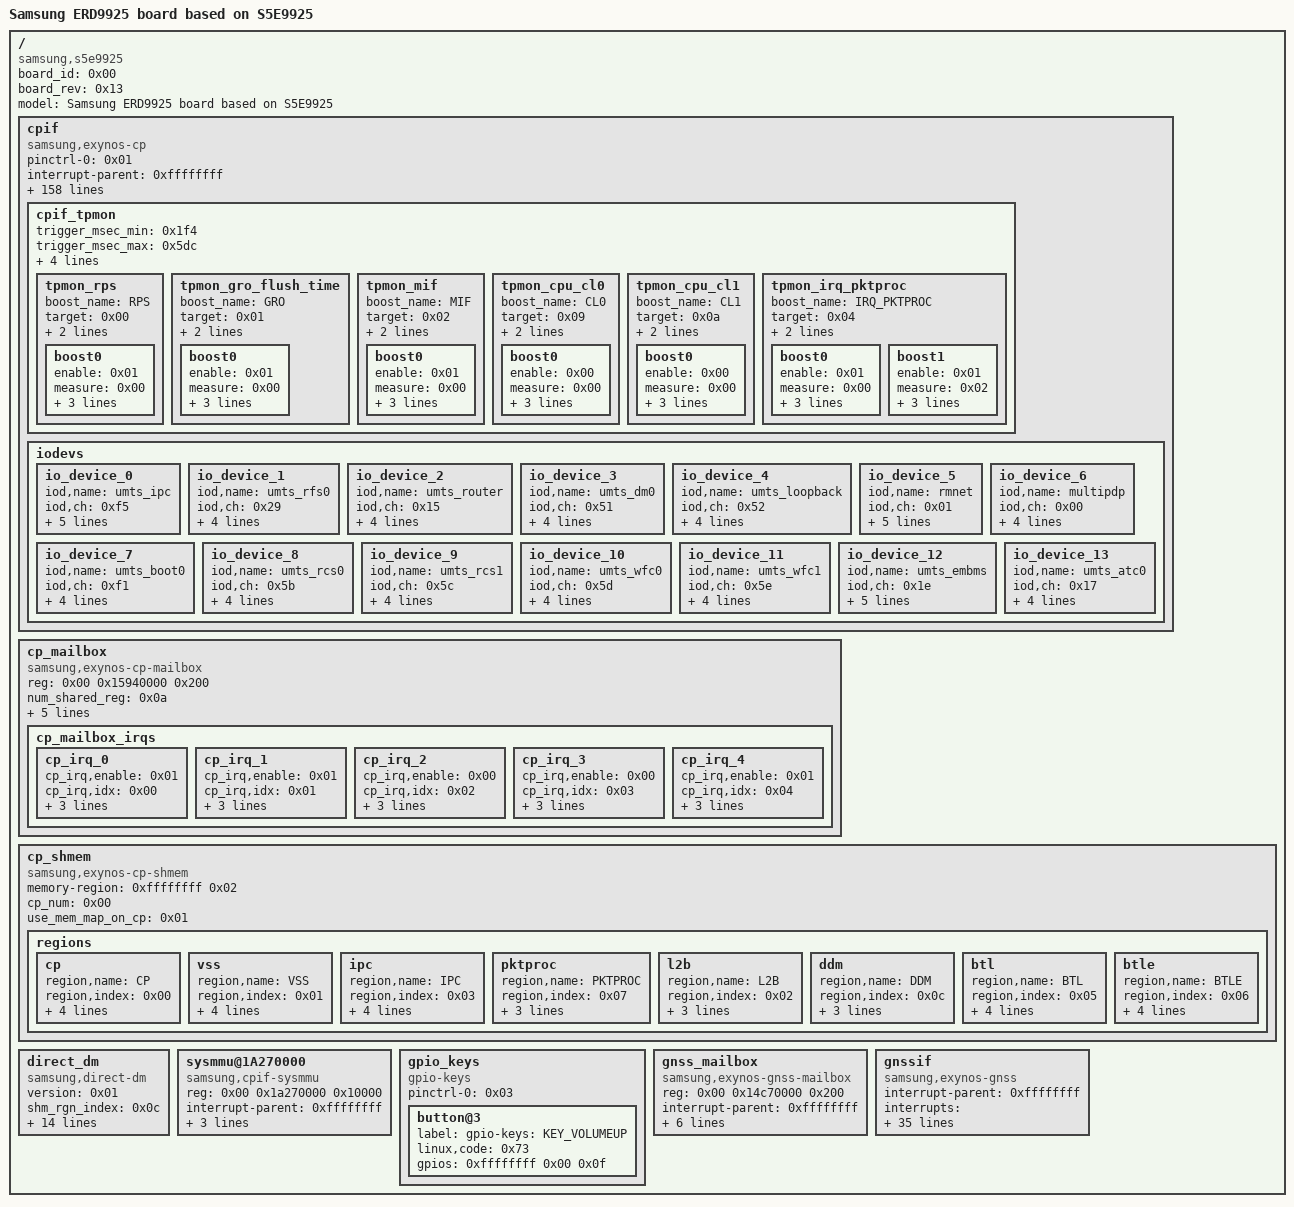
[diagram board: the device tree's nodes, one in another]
/dts-v1/;

/ {
	compatible = "samsung,s5e9925\0samsung,ERD9925";
	board_id = <0x00>;
	board_rev = <0x13>;

	fragment@modemif {
		target-path = "/";

		__overlay__ {
			#address-cells = <0x02>;
			#size-cells = <0x01>;

			cpif {
				compatible = "samsung,exynos-cp";
				status = "okay";
				pinctrl-names = "default";
				pinctrl-0 = <0x01>;
				interrupt-parent = <0xffffffff>;
				interrupts = <0x00 0x275 0x04>;
				interrupt-names = "RESET_REQ";
				ap2cp_cfg_addr = <0x19020000>;
				mif,name = "s5133ap";
				mif,cp_num = <0x00>;
				mif,modem_type = <0x00>;
				mif,protocol = <0x01>;
				mif,ipc_version = <0x32>;
				mif,link_type = <0x00>;
				mif,link_name = "shmem";
				mif,link_attrs = <0x7c8>;
				mif,interrupt_types = <0x00>;
				mif,capability_check = <0x01>;
				mif,int_ap2cp_msg = <0x00>;
				mif,int_ap2cp_wakeup = <0x01>;
				mif,int_ap2cp_status = <0x02>;
				mif,int_ap2cp_active = <0x03>;
				mif,int_ap2cp_lcd_status = <0x04>;
				mif,int_ap2cp_llc_status = <0x05>;
				mif,int_ap2cp_clatinfo_send = <0x06>;
				mif,int_ap2cp_uart_noti = <0x0f>;
				mif,irq_cp2ap_msg = <0x00>;
				mif,irq_cp2ap_status = <0x02>;
				mif,irq_cp2ap_active = <0x03>;
				mif,irq_cp2ap_llc_status = <0x05>;
				mif,irq_cp2ap_clatinfo_ack = <0x06>;
				mif,irq_cp2ap_wakelock = <0x08>;
				mif,irq_cp2ap_ratmode = <0x09>;
				legacy_fmt_head_tail_offset = <0x10>;
				legacy_fmt_buffer_offset = <0x1000>;
				legacy_fmt_txq_size = <0x1000>;
				legacy_fmt_rxq_size = <0x1000>;
				legacy_raw_head_tail_offset = <0x20>;
				legacy_raw_buffer_offset = <0x3000>;
				legacy_raw_txq_size = <0x1fd000>;
				legacy_raw_rxq_size = <0x200000>;
				legacy_raw_qos_head_tail_offset = <0x30>;
				legacy_raw_qos_buffer_offset = <0x400000>;
				legacy_raw_qos_txq_size = <0x100000>;
				legacy_raw_qos_rxq_size = <0x100000>;
				legacy_raw_rx_buffer_cached = <0x00>;
				offset_cmsg_offset = <0x60>;
				offset_srinfo_offset = <0x64>;
				offset_clk_table_offset = <0x68>;
				offset_buff_desc_offset = <0x6c>;
				offset_capability_offset = <0x70>;
				cmsg_offset = <0xc0>;
				srinfo_offset = <0x300>;
				srinfo_size = <0x800>;
				clk_table_offset = <0x200>;
				buff_desc_offset = <0xc00>;
				capability_offset = <0xa0>;
				ap_capability_0 = <0x00>;
				ap_capability_1 = <0x00>;
				ap2cp_msg = <0x03 0x00>;
				cp2ap_msg = <0x03 0x04>;
				ap2cp_united_status = <0x03 0x08>;
				cp2ap_united_status = <0x03 0x0c>;
				ap2cp_llc_status = <0x03 0x10>;
				cp2ap_llc_status = <0x03 0x14>;
				ap2cp_clatinfo_xlat_v4_addr = <0x03 0x18>;
				ap2cp_clatinfo_xlat_addr_0 = <0x03 0x1c>;
				ap2cp_clatinfo_xlat_addr_1 = <0x03 0x20>;
				ap2cp_clatinfo_xlat_addr_2 = <0x03 0x24>;
				ap2cp_clatinfo_xlat_addr_3 = <0x03 0x28>;
				ap2cp_clatinfo_index = <0x03 0x2c>;
				ap2cp_kerneltime_sec = <0x03 0x38>;
				ap2cp_kerneltime_usec = <0x03 0x3c>;
				sbi_lcd_status_mask = <0x01>;
				sbi_lcd_status_pos = <0x1b>;
				sbi_crash_type_mask = <0x0f>;
				sbi_crash_type_pos = <0x17>;
				sbi_ext_backtrace_mask = <0x01>;
				sbi_ext_backtrace_pos = <0x11>;
				sbi_ext_backtrace_ext_mask = <0x01>;
				sbi_ext_backtrace_ext_pos = <0x12>;
				sbi_uart_noti_mask = <0x01>;
				sbi_uart_noti_pos = <0x10>;
				sbi_ds_det_mask = <0x03>;
				sbi_ds_det_pos = <0x0e>;
				sbi_sys_rev_mask = <0xff>;
				sbi_sys_rev_pos = <0x06>;
				sbi_pda_active_mask = <0x01>;
				sbi_pda_active_pos = <0x05>;
				sbi_ap_status_mask = <0x0f>;
				sbi_ap_status_pos = <0x01>;
				sbi_cp_rat_mode_mask = <0x3f>;
				sbi_cp_rat_mode_pos = <0x1a>;
				sbi_cp_evs_mode_mask = <0x01>;
				sbi_cp_evs_mode_pos = <0x07>;
				sbi_cp2ap_wakelock_mask = <0x01>;
				sbi_cp2ap_wakelock_pos = <0x06>;
				sbi_lte_active_mask = <0x01>;
				sbi_lte_active_pos = <0x05>;
				sbi_cp_status_mask = <0x0f>;
				sbi_cp_status_pos = <0x01>;
				sbi_ap_llc_request_mask = <0x01>;
				sbi_ap_llc_request_pos = <0x0e>;
				sbi_ap_llc_target_mask = <0x01>;
				sbi_ap_llc_target_pos = <0x0d>;
				sbi_ap_llc_return_mask = <0x0f>;
				sbi_ap_llc_return_pos = <0x09>;
				sbi_ap_llc_alloc_mask = <0x01>;
				sbi_ap_llc_alloc_pos = <0x08>;
				sbi_ap_llc_way_mask = <0xff>;
				sbi_ap_llc_way_pos = <0x00>;
				sbi_cp_llc_request_mask = <0x01>;
				sbi_cp_llc_request_pos = <0x0e>;
				sbi_cp_llc_target_mask = <0x01>;
				sbi_cp_llc_target_pos = <0x0d>;
				sbi_cp_llc_return_mask = <0x0f>;
				sbi_cp_llc_return_pos = <0x09>;
				sbi_cp_llc_alloc_mask = <0x01>;
				sbi_cp_llc_alloc_pos = <0x08>;
				sbi_cp_llc_way_mask = <0xff>;
				sbi_cp_llc_way_pos = <0x00>;
				cp_btl_node_name = "ramdump_memshare";
				cp_btl_support_extension = <0x01>;
				cp_btl_extension_dram_size = <0x1000>;
				pktproc_use_36bit_addr = <0x01>;
				pktproc_cp_base = <0x0a 0x90800000>;
				pktproc_dl_support = <0x01>;
				pktproc_dl_version = <0x02>;
				pktproc_dl_info_rgn_offset = <0x00>;
				pktproc_dl_info_rgn_size = <0x1000>;
				pktproc_dl_desc_rgn_offset = <0x2000>;
				pktproc_dl_desc_rgn_size = <0x1fe000>;
				pktproc_dl_buff_rgn_offset = <0x700000>;
				pktproc_dl_buff_rgn_size = <0x1000000>;
				pktproc_dl_info_rgn_cached = <0x00>;
				pktproc_dl_desc_rgn_cached = <0x00>;
				pktproc_dl_buff_rgn_cached = <0x01>;
				pktproc_dl_desc_mode = <0x01>;
				pktproc_dl_num_queue = <0x01>;
				pktproc_dl_use_exclusive_irq = <0x01>;
				pktproc_dl_exclusive_irq_idx = <0x01 0x02 0x03 0x04>;
				pktproc_dl_use_netrx_mng = <0x01>;
				pktproc_dl_netrx_capacity = <0x2710>;
				pktproc_dl_use_hw_iocc = <0x00>;
				pktproc_dl_max_packet_size = <0x800>;
				pktproc_dl_use_dedicated_baaw = <0x01>;
				pktproc_ul_support = <0x01>;
				pktproc_ul_info_rgn_offset = <0x1000>;
				pktproc_ul_info_rgn_size = <0x1000>;
				pktproc_ul_desc_rgn_offset = <0x200000>;
				pktproc_ul_desc_rgn_size = <0x100000>;
				pktproc_ul_buff_rgn_offset = <0x300000>;
				pktproc_ul_buff_rgn_size = <0x400000>;
				pktproc_ul_padding_required = <0x01>;
				pktproc_ul_num_queue = <0x02>;
				pktproc_ul_max_packet_size = <0x800>;
				pktproc_ul_hiprio_ack_only = <0x01>;
				pktproc_ul_info_rgn_cached = <0x00>;
				pktproc_ul_desc_rgn_cached = <0x00>;
				pktproc_ul_buff_rgn_cached = <0x00>;
				pktproc_ul_use_hw_iocc = <0x00>;
				devfreq_use_dfs_max_freq = <0x00>;
				devfreq_cal_id_mif = <0xb040000>;

				cpif_tpmon {
					trigger_msec_min = <0x1f4>;
					trigger_msec_max = <0x5dc>;
					monitor_interval_msec = <0x3e8>;
					monitor_hold_msec = <0xbb8>;
					monitor_stop_mbps = <0x0f>;
					boost_hold_msec = <0x1770>;

					tpmon_rps {
						boost_name = "RPS";
						target = <0x00>;
						extra_idx = <0x00>;
						level = <0x03 0x30>;

						boost0 {
							enable = <0x01>;
							measure = <0x00>;
							proto = <0x00>;
							boost_threshold = <0x12c>;
							unboost_threshold_mbps = <0x78>;
						};
					};

					tpmon_gro_flush_time {
						boost_name = "GRO";
						target = <0x01>;
						extra_idx = <0x00>;
						level = <0x1e8480 0x1e8480 0x1e8480>;

						boost0 {
							enable = <0x01>;
							measure = <0x00>;
							proto = <0x00>;
							boost_threshold = <0x64 0xc8>;
							unboost_threshold_mbps = <0x32 0x78>;
						};
					};

					tpmon_mif {
						boost_name = "MIF";
						target = <0x02>;
						extra_idx = <0x00>;
						level = <0x00 0xf78f0>;

						boost0 {
							enable = <0x01>;
							measure = <0x00>;
							proto = <0x01>;
							boost_threshold = <0x2bc>;
							unboost_threshold_mbps = <0x12c>;
						};
					};

					tpmon_cpu_cl0 {
						boost_name = "CL0";
						target = <0x09>;
						extra_idx = <0x00>;
						level = <0x00 0xea600 0x119400>;

						boost0 {
							enable = <0x00>;
							measure = <0x00>;
							proto = <0x01>;
							boost_threshold = <0x64 0x12c>;
							unboost_threshold_mbps = <0x28 0x78>;
						};
					};

					tpmon_cpu_cl1 {
						boost_name = "CL1";
						target = <0x0a>;
						extra_idx = <0x04>;
						level = <0x00 0xbb800 0x119400 0x177000>;

						boost0 {
							enable = <0x00>;
							measure = <0x00>;
							proto = <0x01>;
							boost_threshold = <0x1f4 0x2bc 0x5dc>;
							unboost_threshold_mbps = <0xc8 0x12c 0x258>;
						};
					};

					tpmon_irq_pktproc {
						boost_name = "IRQ_PKTPROC";
						target = <0x04>;
						extra_idx = <0x01>;
						level = <0x04 0x40>;

						boost0 {
							enable = <0x01>;
							measure = <0x00>;
							proto = <0x00>;
							boost_threshold = <0x7d0>;
							unboost_threshold_mbps = <0x320>;
						};

						boost1 {
							enable = <0x01>;
							measure = <0x02>;
							proto = <0x00>;
							boost_threshold = <0x1770>;
							unboost_threshold_mbps = <0x7d0>;
						};
					};
				};

				iodevs {

					io_device_0 {
						iod,name = "umts_ipc";
						iod,ch = <0xf5>;
						iod,format = <0x00>;
						iod,io_type = <0x01>;
						iod,link_type = <0x00>;
						iod,attrs = <0x2000>;
						iod,ch_count = <0x02>;
					};

					io_device_1 {
						iod,name = "umts_rfs0";
						iod,ch = <0x29>;
						iod,format = <0x01>;
						iod,io_type = <0x01>;
						iod,link_type = <0x00>;
						iod,attrs = <0x00>;
					};

					io_device_2 {
						iod,name = "umts_router";
						iod,ch = <0x15>;
						iod,format = <0x01>;
						iod,io_type = <0x01>;
						iod,link_type = <0x00>;
						iod,attrs = <0x00>;
					};

					io_device_3 {
						iod,name = "umts_dm0";
						iod,ch = <0x51>;
						iod,format = <0x01>;
						iod,io_type = <0x01>;
						iod,link_type = <0x00>;
						iod,attrs = <0x4000>;
					};

					io_device_4 {
						iod,name = "umts_loopback";
						iod,ch = <0x52>;
						iod,format = <0x01>;
						iod,io_type = <0x01>;
						iod,link_type = <0x00>;
						iod,attrs = <0x00>;
					};

					io_device_5 {
						iod,name = "rmnet";
						iod,ch = <0x01>;
						iod,format = <0x01>;
						iod,io_type = <0x02>;
						iod,link_type = <0x00>;
						iod,attrs = <0x2000>;
						iod,ch_count = <0x08>;
					};

					io_device_6 {
						iod,name = "multipdp";
						iod,ch = <0x00>;
						iod,format = <0x03>;
						iod,io_type = <0x03>;
						iod,link_type = <0x00>;
						iod,attrs = <0x00>;
					};

					io_device_7 {
						iod,name = "umts_boot0";
						iod,ch = <0xf1>;
						iod,format = <0x04>;
						iod,io_type = <0x00>;
						iod,link_type = <0x00>;
						iod,attrs = <0x200>;
					};

					io_device_8 {
						iod,name = "umts_rcs0";
						iod,ch = <0x5b>;
						iod,format = <0x00>;
						iod,io_type = <0x01>;
						iod,link_type = <0x00>;
						iod,attrs = <0x00>;
					};

					io_device_9 {
						iod,name = "umts_rcs1";
						iod,ch = <0x5c>;
						iod,format = <0x01>;
						iod,io_type = <0x01>;
						iod,link_type = <0x00>;
						iod,attrs = <0x00>;
					};

					io_device_10 {
						iod,name = "umts_wfc0";
						iod,ch = <0x5d>;
						iod,format = <0x00>;
						iod,io_type = <0x01>;
						iod,link_type = <0x00>;
						iod,attrs = <0x00>;
					};

					io_device_11 {
						iod,name = "umts_wfc1";
						iod,ch = <0x5e>;
						iod,format = <0x01>;
						iod,io_type = <0x01>;
						iod,link_type = <0x00>;
						iod,attrs = <0x00>;
					};

					io_device_12 {
						iod,name = "umts_embms";
						iod,ch = <0x1e>;
						iod,format = <0x01>;
						iod,io_type = <0x02>;
						iod,link_type = <0x00>;
						iod,attrs = <0x2000>;
						iod,ch_count = <0x02>;
					};

					io_device_13 {
						iod,name = "umts_atc0";
						iod,ch = <0x17>;
						iod,format = <0x01>;
						iod,io_type = <0x01>;
						iod,link_type = <0x00>;
						iod,attrs = <0x00>;
					};
				};
			};

			cp_mailbox {
				compatible = "samsung,exynos-cp-mailbox";
				reg = <0x00 0x15940000 0x200>;
				num_shared_reg = <0x0a>;
				shared_reg_offset = <0x100>;
				use_sw_reset_reg = <0x00>;
				interrupt-parent = <0xffffffff>;
				interrupts = <0x00 0x2b 0x04 0x00 0x2c 0x04 0x00 0x2d 0x04 0x00 0x2e 0x04 0x00 0x2f 0x04>;

				cp_mailbox_irqs {

					cp_irq_0 {
						cp_irq,enable = <0x01>;
						cp_irq,idx = <0x00>;
						cp_irq,name = "cp_mbox_irq_0";
						cp_irq,sfr = <0x00 0x10 0x14 0x00>;
						cp_irq,affinity = <0x03>;
					};

					cp_irq_1 {
						cp_irq,enable = <0x01>;
						cp_irq,idx = <0x01>;
						cp_irq,name = "cp_mbox_irq_1";
						cp_irq,sfr = <0x28 0x00 0x14 0x00>;
						cp_irq,affinity = <0x03>;
					};

					cp_irq_2 {
						cp_irq,enable = <0x00>;
						cp_irq,idx = <0x02>;
						cp_irq,name = "cp_mbox_irq_2";
						cp_irq,sfr = <0x3c 0x00 0x14 0x00>;
						cp_irq,affinity = <0x02>;
					};

					cp_irq_3 {
						cp_irq,enable = <0x00>;
						cp_irq,idx = <0x03>;
						cp_irq,name = "cp_mbox_irq_3";
						cp_irq,sfr = <0x50 0x00 0x14 0x00>;
						cp_irq,affinity = <0x01>;
					};

					cp_irq_4 {
						cp_irq,enable = <0x01>;
						cp_irq,idx = <0x04>;
						cp_irq,name = "cp_mbox_irq_4";
						cp_irq,sfr = <0x64 0x00 0x14 0x00>;
						cp_irq,affinity = <0x02>;
					};
				};
			};

			cp_shmem {
				compatible = "samsung,exynos-cp-shmem";
				memory-region = <0xffffffff 0x02>;
				cp_num = <0x00>;
				use_mem_map_on_cp = <0x01>;

				regions {

					cp {
						region,name = "CP";
						region,index = <0x00>;
						region,rmem = <0x00>;
						region,offset = <0x00>;
						region,size = <0xd000000>;
						region,cached = <0x00>;
					};

					vss {
						region,name = "VSS";
						region,index = <0x01>;
						region,rmem = <0x00>;
						region,offset = <0xd000000>;
						region,size = <0x800000>;
						region,cached = <0x00>;
					};

					ipc {
						region,name = "IPC";
						region,index = <0x03>;
						region,rmem = <0x01>;
						region,offset = <0x00>;
						region,size = <0x800000>;
						region,cached = <0x00>;
					};

					pktproc {
						region,name = "PKTPROC";
						region,index = <0x07>;
						region,rmem = <0x01>;
						region,offset = <0x800000>;
						region,size = <0x800000>;
					};

					l2b {
						region,name = "L2B";
						region,index = <0x02>;
						region,rmem = <0x01>;
						region,offset = <0x1000000>;
						region,size = <0xac00000>;
					};

					ddm {
						region,name = "DDM";
						region,index = <0x0c>;
						region,rmem = <0x01>;
						region,offset = <0xbc00000>;
						region,size = <0x400000>;
					};

					btl {
						region,name = "BTL";
						region,index = <0x05>;
						region,rmem = <0x01>;
						region,offset = <0xc000000>;
						region,size = <0x2000000>;
						region,cached = <0x00>;
					};

					btle {
						region,name = "BTLE";
						region,index = <0x06>;
						region,rmem = <0x01>;
						region,offset = <0xe000000>;
						region,size = <0x2000000>;
						region,cached = <0x00>;
					};
				};
			};

			direct_dm {
				compatible = "samsung,direct-dm";
				version = <0x01>;
				shm_rgn_index = <0x0c>;
				hw_iocc = <0x00>;
				info_desc_rgn_cached = <0x00>;
				buff_rgn_cached = <0x00>;
				info_rgn_offset = <0x00>;
				info_rgn_size = <0x100>;
				desc_rgn_offset = <0x100>;
				desc_rgn_size = <0x7f00>;
				buff_rgn_offset = <0x8000>;
				max_packet_size = <0x8000>;
				usb_req_num = <0x80>;
				irq_index = <0x04>;
				use_rx_task = <0x00>;
				use_rx_timer = <0x01>;
				rx_timer_period_msec = <0x3e8>;
			};

			sysmmu@1A270000 {
				compatible = "samsung,cpif-sysmmu";
				reg = <0x00 0x1a270000 0x10000>;
				interrupt-parent = <0xffffffff>;
				interrupts = <0x00 0x281 0x04>;
				interrupt-names = "SYSMMU_MODEM_S1";
				qos = <0x0f>;
				port-name = "CPIF";
				#iommu-cells = <0x00>;
				phandle = <0x05>;
			};
		};
	};

	fragment@0 {
		target = <0xffffffff>;

		__overlay__ {

			tray_detect {
				samsung,pins = "gpm14-0";
				samsung,pin-function = <0x0f>;
				samsung,pin-pud = <0x00>;
				phandle = <0x01>;
			};
		};
	};

	fragment@1 {
		target = <0xffffffff>;

		__overlay__ {
			#address-cells = <0x02>;
			#size-cells = <0x01>;

			cp_rmem1 {
				compatible = "exynos,modem_if";
				reg = <0x08 0x90000000 0x10000000>;
				rmem_index = <0x01>;
				phandle = <0x02>;
			};
		};
	};

	fragment@model {
		target-path = "/";

		__overlay__ {
			#address-cells = <0x02>;
			#size-cells = <0x01>;
			model = "Samsung ERD9925 board based on S5E9925";

			gpio_keys {
				status = "okay";
				compatible = "gpio-keys";
				pinctrl-names = "default";
				pinctrl-0 = <0x03>;

				button@3 {
					label = "gpio-keys: KEY_VOLUMEUP";
					linux,code = <0x73>;
					gpios = <0xffffffff 0x00 0x0f>;
				};
			};

			gnss_mailbox {
				status = "okay";
				compatible = "samsung,exynos-gnss-mailbox";
				reg = <0x00 0x14c70000 0x200>;
				interrupt-parent = <0xffffffff>;
				interrupts = <0x00 0x31 0x04>;
				mbox,name = "gnss_mailbox";
				mbox,id = <0x00>;
				num_shared_reg = <0x04>;
				shared_reg_offset = <0x100>;
				use_sw_reset_reg = <0x00>;
				phandle = <0x04>;
			};

			gnssif {
				status = "okay";
				compatible = "samsung,exynos-gnss";
				interrupt-parent = <0xffffffff>;
				interrupts = <0x00 0x22 0x04 0x00 0x1de 0x01 0x00 0x1dd 0x04 0x00 0x1dc 0x01>;
				interrupt-names = "ACTIVE\0WATCHDOG\0WAKEUP\0SW_INIT";
				shmem,name = "KEPLER";
				device_node_name = "gnss_ipc";
				mbox_info = <0x04>;
				mbx,int_bcmd = <0x00>;
				mbx,int_req_fault_info = <0x01>;
				mbx,int_ipc_msg = <0x02>;
				mbx,int_ack_wake_set = <0x03>;
				mbx,int_ack_wake_clr = <0x04>;
				mbx,irq_bcmd = <0x00>;
				mbx,irq_rsp_fault_info = <0x01>;
				mbx,irq_ipc_msg = <0x02>;
				mbx,irq_req_wake_clr = <0x04>;
				mbx,irq_simple_lock = <0x0f>;
				mbx,reg_bcmd_ctrl = <0x00 0x01 0x02 0x03>;
				memory-region = <0xffffffff>;
				reg_rx_ipc_msg = <0x01 0x05>;
				reg_tx_ipc_msg = <0x01 0x04>;
				reg_rx_head = <0x01 0x03>;
				reg_rx_tail = <0x01 0x02>;
				reg_tx_head = <0x01 0x01>;
				reg_tx_tail = <0x01 0x00>;
				fault_info = <0x01 0x200000 0x180000>;
				shmem,code_offset = <0x00>;
				shmem,code_allowed_size = <0x380000>;
				shmem,ipc_offset = <0x380000>;
				shmem,ipc_size = <0x80000>;
				shmem,ipc_rx_offset = <0x00>;
				shmem,ipc_rx_size = <0x40000>;
				shmem,ipc_tx_offset = <0x40000>;
				shmem,ipc_tx_size = <0x3ff80>;
				shmem,ipc_reg_offset = <0x7ff80>;
				shmem,ipc_reg_size = <0x80>;
				shmem,base_addr = <0x60000000>;
				shmem,base_addr_2nd = <0xa0000000>;
			};
		};
	};

	fragment@2 {
		target = <0xffffffff>;

		__overlay__ {
			status = "okay";
		};
	};

	fragment@3 {
		target = <0xffffffff>;

		__overlay__ {

			key-volup {
				samsung,pins = "gpa3-0";
				samsung,pin-function = <0x0f>;
				samsung,pin-pud = <0x03>;
				samsung,pin-drv = <0x03>;
				phandle = <0x03>;
			};
		};
	};

	fragment@4 {
		target = <0xffffffff>;

		__overlay__ {

			pm-wrstbi {
				samsung,pins = "gpm21-0";
				samsung,pin-con-pdn = <0x03>;
				samsung,pin-pud-pdn = <0x00>;
				phandle = <0x06>;
			};
		};
	};

	fragment@5 {
		target = <0xffffffff>;

		__overlay__ {

			smpl-warn {
				samsung,pins = "gpg0-4";
				samsung,pin-function = <0x0f>;
				samsung,pin-pud = <0x00>;
				samsung,pin-drv = <0x00>;
				phandle = <0x07>;
			};
		};
	};

	fragment@6 {
		target = <0xffffffff>;

		__overlay__ {
			#address-cells = <0x01>;
			#size-cells = <0x00>;

			drmpanel {
				compatible = "samsung,command-ctrl";
				reset-gpios = <0xffffffff 0x00 0x00>;
				reg = <0x00>;
				pinctrl-names = "default";
				pinctrl-0 = <0xffffffff>;
			};
		};
	};

	fragment@7 {
		target = <0xffffffff>;

		__overlay__ {
			status = "okay";
			dp,aux_sw_oe = <0xffffffff 0x00 0x00>;
			dp,sbu_sw_sel = <0xffffffff 0x01 0x00>;
			pinctrl-names = "default";
		};
	};

	fragment@8 {
		target = <0xffffffff>;

		__overlay__ {

			drmpanel {

				samsung_emulation_video_panel {
					samsung,panel-name = "samsung emulation panel";
					phandle = <0x08>;

					display-timings {

						1080x2400@60 {
							exynos,mode-type = <0x48>;
							exynos,refresh-rate = <0x3c>;
							exynos,hactive = <0x438>;
							exynos,hfront-porch = <0x14>;
							exynos,hsync-len = <0x02>;
							exynos,hback-porch = <0x14>;
							exynos,vactive = <0x960>;
							exynos,vfront-porch = <0x14>;
							exynos,vsync-len = <0x02>;
							exynos,vback-porch = <0x14>;
							exynos,mode-flags = <0x00>;
							exynos,bpc = <0x08>;
							exynos,lp-mode = <0x00>;
							exynos,dsc-en = <0x00>;
							exynos,on-cmds = <0x01 0x11 0x00 0x01 0x29 0x00>;
							exynos,off-cmds = <0x01 0x10 0x00 0x01 0x28 0x00>;
						};
					};
				};
			};
		};
	};

	fragment@9 {
		target = <0xffffffff>;

		__overlay__ {

			drmpanel {

				s6e3hab_1440_3200_cmd {
					samsung,panel-name = "samsung s6e3hab 1440x3200 command mode panel";
					samsung,max-brightness = <0x3ff>;
					samsung,default-brightness = <0x1ff>;
					samsung,data-lane-count = <0x04>;
					samsung,doze-supported;
					samsung,reset-sequence = <0x01 0x00 0x01>;
					samsung,reset-udelay = <0x00 0x1388 0x1388 0x2710>;
					samsung,lcd-size-mm = <0x4b 0xa5>;
					phandle = <0x09>;

					display-timings {

						1440x3200@60 {
							exynos,mode-type = <0x48>;
							exynos,refresh-rate = <0x3c>;
							exynos,hactive = <0x5a0>;
							exynos,hfront-porch = <0x02>;
							exynos,hsync-len = <0x02>;
							exynos,hback-porch = <0x02>;
							exynos,vactive = <0xc80>;
							exynos,vfront-porch = <0x08>;
							exynos,vsync-len = <0x01>;
							exynos,vback-porch = <0x0f>;
							exynos,clock-frequency = <0x444a2>;
							exynos,mode-flags = <0x0a>;
							exynos,bpc = <0x08>;
							exynos,lp-mode = <0x00>;
							exynos,dsc-en = <0x01>;
							exynos,dsc-count = <0x02>;
							exynos,dsc-slice-count = <0x02>;
							exynos,dsc-slice-height = <0x28>;
							exynos,pre-pps-cmds = <0x03 0x9f 0xa5 0xa5 0x00>;
							exynos,pps-cmds = <0x58 0x11 0x00 0x00 0x89 0x30 0x80 0x0c 0x80 0x05 0xa0 0x00 0x28 0x02 0xd0 0x02 0xd0 0x02 0x00 0x02 0x68 0x00 0x20 0x04 0x6c 0x00 0x0a 0x00 0x0c 0x02 0x77 0x01 0xe9 0x18 0x00 0x10 0xf0 0x03 0x0c 0x20 0x00 0x06 0x0b 0x0b 0x33 0x0e 0x1c 0x2a 0x38 0x46 0x54 0x62 0x69 0x70 0x77 0x79 0x7b 0x7d 0x7e 0x01 0x02 0x01 0x00 0x09 0x40 0x09 0xbe 0x19 0xfc 0x19 0xfa 0x19 0xf8 0x1a 0x38 0x1a 0x78 0x1a 0xb6 0x2a 0xf6 0x2b 0x34 0x2b 0x74 0x3b 0x74 0x6b 0xf4 0x00>;
							exynos,post-pps-cmds = <0x03 0x9f 0x5a 0x5a 0x00>;
							exynos,on-cmds = <0x03 0xf0 0x5a 0x5a 0x00 0x03 0xfc 0x5a 0x5a 0x00 0x01 0x11 0xc8 0x0a 0xb9 0x00 0xc0 0x8c 0x09 0x00 0x00 0x00 0x11 0x03 0x00 0x02 0x53 0x20 0x00 0x03 0x51 0xff 0x7f 0x00 0x01 0x35 0x00 0x03 0xed 0x04 0x44 0x00 0x05 0xb9 0x00 0xc0 0x8c 0x09 0x00>;
							exynos,vref-cmds = <0x03 0xf0 0x5a 0x5a 0x00 0x05 0xb9 0x01 0xa0 0x34 0x09 0x00 0x03 0x9f 0xa5 0xa5 0x00 0x02 0x60 0x00 0x00 0x03 0x9f 0x5a 0x5a 0x00 0x02 0xf7 0x0f 0x00 0x03 0xf0 0xa5 0xa5 0x00>;
							exynos,mres-cmds = <0x05 0x2a 0x00 0x00 0x05 0x9f 0x00 0x05 0x2b 0x00 0x00 0x0c 0x7f 0x00 0x03 0xf0 0x5a 0x5a 0x00 0x02 0xba 0x01 0x00 0x03 0xf0 0xa5 0xa5 0x00>;
							exynos,disp-on-cmds = <0x03 0x9f 0xa5 0xa5 0x00 0x01 0x29 0x00 0x03 0x9f 0x5a 0x5a 0x00>;
							exynos,off-cmds = <0x01 0x10 0x00 0x01 0x28 0x00>;
						};

						1080x2400@60 {
							exynos,mode-type = <0x40>;
							exynos,refresh-rate = <0x3c>;
							exynos,hactive = <0x438>;
							exynos,hfront-porch = <0x02>;
							exynos,hsync-len = <0x02>;
							exynos,hback-porch = <0x02>;
							exynos,vactive = <0x960>;
							exynos,vfront-porch = <0x08>;
							exynos,vsync-len = <0x01>;
							exynos,vback-porch = <0x0f>;
							exynos,clock-frequency = <0x268fc>;
							exynos,mode-flags = <0x0a>;
							exynos,bpc = <0x08>;
							exynos,lp-mode = <0x00>;
							exynos,dsc-en = <0x01>;
							exynos,dsc-count = <0x02>;
							exynos,dsc-slice-count = <0x02>;
							exynos,dsc-slice-height = <0x28>;
							exynos,pre-pps-cmds = <0x03 0x9f 0xa5 0xa5 0x00>;
							exynos,pps-cmds = <0x58 0x11 0x00 0x00 0x89 0x30 0x80 0x09 0x60 0x04 0x38 0x00 0x28 0x02 0x1c 0x02 0x1c 0x02 0x00 0x02 0x0e 0x00 0x20 0x03 0xdd 0x00 0x07 0x00 0x0c 0x02 0x77 0x02 0x8b 0x18 0x00 0x10 0xf0 0x03 0x0c 0x20 0x00 0x06 0x0b 0x0b 0x33 0x0e 0x1c 0x2a 0x38 0x46 0x54 0x62 0x69 0x70 0x77 0x79 0x7b 0x7d 0x7e 0x01 0x02 0x01 0x00 0x09 0x40 0x09 0xbe 0x19 0xfc 0x19 0xfa 0x19 0xf8 0x1a 0x38 0x1a 0x78 0x1a 0xb6 0x2a 0xf6 0x2b 0x34 0x2b 0x74 0x3b 0x74 0x6b 0xf4 0x00>;
							exynos,post-pps-cmds = <0x03 0x9f 0x5a 0x5a 0x00>;
							exynos,on-cmds = <0x03 0xf0 0x5a 0x5a 0x00 0x03 0xfc 0x5a 0x5a 0x00 0x01 0x11 0xc8 0x0a 0xb9 0x00 0xc0 0x8c 0x09 0x00 0x00 0x00 0x11 0x03 0x00 0x02 0x53 0x20 0x00 0x03 0x51 0xff 0x7f 0x00 0x01 0x35 0x00 0x03 0xed 0x04 0x44 0x00 0x05 0xb9 0x00 0xc0 0x8c 0x09 0x00>;
							exynos,vref-cmds = <0x03 0xf0 0x5a 0x5a 0x00 0x05 0xb9 0x01 0xa0 0x34 0x09 0x00 0x03 0x9f 0xa5 0xa5 0x00 0x02 0x60 0x00 0x00 0x03 0x9f 0x5a 0x5a 0x00 0x02 0xf7 0x0f 0x00 0x03 0xf0 0xa5 0xa5 0x00>;
							exynos,mres-cmds = <0x05 0x2a 0x00 0x00 0x04 0x37 0x00 0x05 0x2b 0x00 0x00 0x09 0x5f 0x00 0x03 0xf0 0x5a 0x5a 0x00 0x02 0xba 0x02 0x00 0x03 0xf0 0xa5 0xa5 0x00>;
							exynos,disp-on-cmds = <0x03 0x9f 0xa5 0xa5 0x00 0x01 0x29 0x00 0x03 0x9f 0x5a 0x5a 0x00>;
							exynos,off-cmds = <0x01 0x10 0x00 0x01 0x28 0x00>;
						};

						1080x2400@120 {
							exynos,mode-type = <0x40>;
							exynos,refresh-rate = <0x78>;
							exynos,hactive = <0x438>;
							exynos,hfront-porch = <0x02>;
							exynos,hsync-len = <0x02>;
							exynos,hback-porch = <0x02>;
							exynos,vactive = <0x960>;
							exynos,vfront-porch = <0x08>;
							exynos,vsync-len = <0x01>;
							exynos,vback-porch = <0x0f>;
							exynos,clock-frequency = <0x4d1f6>;
							exynos,mode-flags = <0x0a>;
							exynos,bpc = <0x08>;
							exynos,lp-mode = <0x00>;
							exynos,dsc-en = <0x01>;
							exynos,dsc-count = <0x02>;
							exynos,dsc-slice-count = <0x02>;
							exynos,dsc-slice-height = <0x28>;
							exynos,pre-pps-cmds = <0x03 0x9f 0xa5 0xa5 0x00>;
							exynos,post-pps-cmds = <0x03 0x9f 0x5a 0x5a 0x00>;
							exynos,pps-cmds = <0x58 0x11 0x00 0x00 0x89 0x30 0x80 0x09 0x60 0x04 0x38 0x00 0x28 0x02 0x1c 0x02 0x1c 0x02 0x00 0x02 0x0e 0x00 0x20 0x03 0xdd 0x00 0x07 0x00 0x0c 0x02 0x77 0x02 0x8b 0x18 0x00 0x10 0xf0 0x03 0x0c 0x20 0x00 0x06 0x0b 0x0b 0x33 0x0e 0x1c 0x2a 0x38 0x46 0x54 0x62 0x69 0x70 0x77 0x79 0x7b 0x7d 0x7e 0x01 0x02 0x01 0x00 0x09 0x40 0x09 0xbe 0x19 0xfc 0x19 0xfa 0x19 0xf8 0x1a 0x38 0x1a 0x78 0x1a 0xb6 0x2a 0xf6 0x2b 0x34 0x2b 0x74 0x3b 0x74 0x6b 0xf4 0x00>;
							exynos,on-cmds = <0x03 0xf0 0x5a 0x5a 0x00 0x03 0xfc 0x5a 0x5a 0x00 0x01 0x11 0xc8 0x0a 0xb9 0x00 0xc0 0x8c 0x09 0x00 0x00 0x00 0x11 0x03 0x00 0x02 0x53 0x20 0x00 0x03 0x51 0xff 0x7f 0x00 0x01 0x35 0x00 0x03 0xed 0x04 0x44 0x00 0x05 0xb9 0x00 0xc0 0x8c 0x09 0x00>;
							exynos,vref-cmds = <0x03 0xf0 0x5a 0x5a 0x00 0x05 0xb9 0x01 0x70 0xdc 0x09 0x00 0x03 0x9f 0xa5 0xa5 0x00 0x02 0x60 0x20 0x00 0x03 0x9f 0x5a 0x5a 0x00 0x02 0xf7 0x0f 0x00 0x03 0xf0 0xa5 0xa5 0x00>;
							exynos,mres-cmds = <0x05 0x2a 0x00 0x00 0x04 0x37 0x00 0x05 0x2b 0x00 0x00 0x09 0x5f 0x00 0x03 0xf0 0x5a 0x5a 0x00 0x02 0xba 0x02 0x00 0x03 0xf0 0xa5 0xa5 0x00>;
							exynos,disp-on-cmds = <0x03 0x9f 0xa5 0xa5 0x00 0x01 0x29 0x00 0x03 0x9f 0x5a 0x5a 0x00>;
							exynos,off-cmds = <0x01 0x10 0x00 0x01 0x28 0x00>;
						};

						720x1600@60 {
							exynos,mode-type = <0x40>;
							exynos,refresh-rate = <0x3c>;
							exynos,hactive = <0x2d0>;
							exynos,hfront-porch = <0x02>;
							exynos,hsync-len = <0x02>;
							exynos,hback-porch = <0x02>;
							exynos,vactive = <0x640>;
							exynos,vfront-porch = <0x08>;
							exynos,vsync-len = <0x01>;
							exynos,vback-porch = <0x0f>;
							exynos,clock-frequency = <0x11455>;
							exynos,mode-flags = <0x0a>;
							exynos,bpc = <0x08>;
							exynos,lp-mode = <0x00>;
							exynos,dsc-en = <0x01>;
							exynos,dsc-count = <0x02>;
							exynos,dsc-slice-count = <0x02>;
							exynos,dsc-slice-height = <0x50>;
							exynos,pre-pps-cmds = <0x03 0x9f 0xa5 0xa5 0x00>;
							exynos,pps-cmds = <0x58 0x11 0x00 0x00 0x89 0x30 0x80 0x06 0x40 0x02 0xd0 0x00 0x50 0x01 0x68 0x01 0x68 0x02 0x00 0x01 0xb4 0x00 0x20 0x06 0x2f 0x00 0x05 0x00 0x0c 0x01 0x38 0x01 0xe9 0x18 0x00 0x10 0xf0 0x03 0x0c 0x20 0x00 0x06 0x0b 0x0b 0x33 0x0e 0x1c 0x2a 0x38 0x46 0x54 0x62 0x69 0x70 0x77 0x79 0x7b 0x7d 0x7e 0x01 0x02 0x01 0x00 0x09 0x40 0x09 0xbe 0x19 0xfc 0x19 0xfa 0x19 0xf8 0x1a 0x38 0x1a 0x78 0x1a 0xb6 0x2a 0xf6 0x2b 0x34 0x2b 0x74 0x3b 0x74 0x6b 0xf4 0x00>;
							exynos,post-pps-cmds = <0x03 0x9f 0x5a 0x5a 0x00>;
							exynos,on-cmds = <0x03 0xf0 0x5a 0x5a 0x00 0x03 0xfc 0x5a 0x5a 0x00 0x01 0x11 0xc8 0x0a 0xb9 0x00 0xc0 0x8c 0x09 0x00 0x00 0x00 0x11 0x03 0x00 0x02 0x53 0x20 0x00 0x03 0x51 0xff 0x7f 0x00 0x01 0x35 0x00 0x03 0xed 0x04 0x44 0x00 0x05 0xb9 0x00 0xc0 0x8c 0x09 0x00>;
							exynos,vref-cmds = <0x03 0xf0 0x5a 0x5a 0x00 0x05 0xb9 0x01 0xa0 0x34 0x09 0x00 0x03 0x9f 0xa5 0xa5 0x00 0x02 0x60 0x00 0x00 0x03 0x9f 0x5a 0x5a 0x00 0x02 0xf7 0x0f 0x00 0x03 0xf0 0xa5 0xa5 0x00>;
							exynos,mres-cmds = <0x05 0x2a 0x00 0x00 0x02 0xcf 0x00 0x05 0x2b 0x00 0x00 0x06 0x3f 0x00 0x03 0xf0 0x5a 0x5a 0x00 0x02 0xba 0x00 0x00 0x03 0xf0 0xa5 0xa5 0x00>;
							exynos,disp-on-cmds = <0x03 0x9f 0xa5 0xa5 0x00 0x01 0x29 0x00 0x03 0x9f 0x5a 0x5a 0x00>;
							exynos,off-cmds = <0x01 0x10 0x00 0x01 0x28 0x00>;
						};

						720x1600@120 {
							exynos,mode-type = <0x40>;
							exynos,refresh-rate = <0x78>;
							exynos,hactive = <0x2d0>;
							exynos,hfront-porch = <0x02>;
							exynos,hsync-len = <0x02>;
							exynos,hback-porch = <0x02>;
							exynos,vactive = <0x640>;
							exynos,vfront-porch = <0x08>;
							exynos,vsync-len = <0x01>;
							exynos,vback-porch = <0x0f>;
							exynos,clock-frequency = <0x228ab>;
							exynos,mode-flags = <0x0a>;
							exynos,bpc = <0x08>;
							exynos,lp-mode = <0x00>;
							exynos,dsc-en = <0x01>;
							exynos,dsc-count = <0x02>;
							exynos,dsc-slice-count = <0x02>;
							exynos,dsc-slice-height = <0x50>;
							exynos,pre-pps-cmds = <0x03 0x9f 0xa5 0xa5 0x00>;
							exynos,pps-cmds = <0x58 0x11 0x00 0x00 0x89 0x30 0x80 0x06 0x40 0x02 0xd0 0x00 0x50 0x01 0x68 0x01 0x68 0x02 0x00 0x01 0xb4 0x00 0x20 0x06 0x2f 0x00 0x05 0x00 0x0c 0x01 0x38 0x01 0xe9 0x18 0x00 0x10 0xf0 0x03 0x0c 0x20 0x00 0x06 0x0b 0x0b 0x33 0x0e 0x1c 0x2a 0x38 0x46 0x54 0x62 0x69 0x70 0x77 0x79 0x7b 0x7d 0x7e 0x01 0x02 0x01 0x00 0x09 0x40 0x09 0xbe 0x19 0xfc 0x19 0xfa 0x19 0xf8 0x1a 0x38 0x1a 0x78 0x1a 0xb6 0x2a 0xf6 0x2b 0x34 0x2b 0x74 0x3b 0x74 0x6b 0xf4 0x00>;
							exynos,post-pps-cmds = <0x03 0x9f 0x5a 0x5a 0x00>;
							exynos,on-cmds = <0x03 0xf0 0x5a 0x5a 0x00 0x03 0xfc 0x5a 0x5a 0x00 0x01 0x11 0xc8 0x0a 0xb9 0x00 0xc0 0x8c 0x09 0x00 0x00 0x00 0x11 0x03 0x00 0x02 0x53 0x20 0x00 0x03 0x51 0xff 0x7f 0x00 0x01 0x35 0x00 0x03 0xed 0x04 0x44 0x00 0x05 0xb9 0x00 0xc0 0x8c 0x09 0x00>;
							exynos,vref-cmds = <0x03 0xf0 0x5a 0x5a 0x00 0x05 0xb9 0x01 0x70 0xdc 0x09 0x00 0x03 0x9f 0xa5 0xa5 0x00 0x02 0x60 0x20 0x00 0x03 0x9f 0x5a 0x5a 0x00 0x02 0xf7 0x0f 0x00 0x03 0xf0 0xa5 0xa5 0x00>;
							exynos,mres-cmds = <0x05 0x2a 0x00 0x00 0x02 0xcf 0x00 0x05 0x2b 0x00 0x00 0x06 0x3f 0x00 0x03 0xf0 0x5a 0x5a 0x00 0x02 0xba 0x00 0x00 0x03 0xf0 0xa5 0xa5 0x00>;
							exynos,disp-on-cmds = <0x03 0x9f 0xa5 0xa5 0x00 0x01 0x29 0x00 0x03 0x9f 0x5a 0x5a 0x00>;
							exynos,off-cmds = <0x01 0x10 0x00 0x01 0x28 0x00>;
						};

						1440x3200@30 {
							exynos,mode-type = <0x40>;
							exynos,refresh-rate = <0x1e>;
							exynos,hactive = <0x5a0>;
							exynos,hfront-porch = <0x02>;
							exynos,hsync-len = <0x02>;
							exynos,hback-porch = <0x02>;
							exynos,vactive = <0xc80>;
							exynos,vfront-porch = <0x08>;
							exynos,vsync-len = <0x01>;
							exynos,vback-porch = <0x0f>;
							exynos,clock-frequency = <0x22251>;
							exynos,mode-flags = <0x0a>;
							exynos,bpc = <0x08>;
							exynos,lp-mode = <0x01>;
							exynos,dsc-en = <0x01>;
							exynos,dsc-count = <0x01>;
							exynos,dsc-slice-count = <0x02>;
							exynos,dsc-slice-height = <0x28>;
						};

						1080x2400@30 {
							exynos,mode-type = <0x40>;
							exynos,refresh-rate = <0x1e>;
							exynos,hactive = <0x438>;
							exynos,hfront-porch = <0x02>;
							exynos,hsync-len = <0x02>;
							exynos,hback-porch = <0x02>;
							exynos,vactive = <0x960>;
							exynos,vfront-porch = <0x08>;
							exynos,vsync-len = <0x01>;
							exynos,vback-porch = <0x0f>;
							exynos,clock-frequency = <0x1347e>;
							exynos,mode-flags = <0x0a>;
							exynos,bpc = <0x08>;
							exynos,lp-mode = <0x01>;
							exynos,dsc-en = <0x01>;
							exynos,dsc-count = <0x01>;
							exynos,dsc-slice-count = <0x02>;
							exynos,dsc-slice-height = <0x28>;
						};

						720x1600@30 {
							exynos,mode-type = <0x40>;
							exynos,refresh-rate = <0x1e>;
							exynos,hactive = <0x2d0>;
							exynos,hfront-porch = <0x02>;
							exynos,hsync-len = <0x02>;
							exynos,hback-porch = <0x02>;
							exynos,vactive = <0x640>;
							exynos,vfront-porch = <0x08>;
							exynos,vsync-len = <0x01>;
							exynos,vback-porch = <0x0f>;
							exynos,clock-frequency = <0x8a2b>;
							exynos,mode-flags = <0x0a>;
							exynos,bpc = <0x08>;
							exynos,lp-mode = <0x01>;
							exynos,dsc-en = <0x01>;
							exynos,dsc-count = <0x01>;
							exynos,dsc-slice-count = <0x02>;
							exynos,dsc-slice-height = <0x28>;
						};
					};
				};
			};
		};
	};

	fragment@10 {
		target = <0xffffffff>;

		__overlay__ {
			status = "okay";
		};
	};

	fragment@11 {
		target = <0xffffffff>;

		__overlay__ {

			drmpanel {
				default-panel = "s6e3hab_1440_3200_cmd";
			};
		};
	};

	__symbols__ {
		sysmmu_cpif = "/fragment@modemif/__overlay__/sysmmu@1A270000";
		tray_detect = "/fragment@0/__overlay__/tray_detect";
		cp_rmem1 = "/fragment@1/__overlay__/cp_rmem1";
		gnss_mailbox = "/fragment@model/__overlay__/gnss_mailbox";
		key_volup = "/fragment@3/__overlay__/key-volup";
		pm_wrstbi = "/fragment@4/__overlay__/pm-wrstbi";
		smpl_warn = "/fragment@5/__overlay__/smpl-warn";
		samsung_emulation_video_panel = "/fragment@8/__overlay__/drmpanel/samsung_emulation_video_panel";
		s6e3hab_1440_3200_cmd = "/fragment@9/__overlay__/drmpanel/s6e3hab_1440_3200_cmd";
	};

	__fixups__ {
		gic = "/fragment@modemif/__overlay__/cpif:interrupt-parent:0\0/fragment@modemif/__overlay__/cp_mailbox:interrupt-parent:0\0/fragment@modemif/__overlay__/sysmmu@1A270000:interrupt-parent:0\0/fragment@model/__overlay__/gnss_mailbox:interrupt-parent:0\0/fragment@model/__overlay__/gnssif:interrupt-parent:0";
		cp_rmem = "/fragment@modemif/__overlay__/cp_shmem:memory-region:0";
		pinctrl_1 = "/fragment@0:target:0\0/fragment@4:target:0";
		reserved_memory = "/fragment@1:target:0";
		gpa3 = "/fragment@model/__overlay__/gpio_keys/button@3:gpios:0";
		gnss_rmem = "/fragment@model/__overlay__/gnssif:memory-region:0";
		serial_0 = "/fragment@2:target:0\0/fragment@10:target:0";
		pinctrl_0 = "/fragment@3:target:0";
		pinctrl_7 = "/fragment@5:target:0";
		drmdsim_0 = "/fragment@6:target:0\0/fragment@8:target:0\0/fragment@9:target:0\0/fragment@11:target:0";
		gpc7 = "/fragment@6/__overlay__/drmpanel:reset-gpios:0";
		ddi_rst = "/fragment@6/__overlay__/drmpanel:pinctrl-0:0";
		drmdp = "/fragment@7:target:0";
		s2mps26_gpio = "/fragment@7/__overlay__:dp,aux_sw_oe:0\0/fragment@7/__overlay__:dp,sbu_sw_sel:0";
	};

	__local_fixups__ {

		fragment@modemif {

			__overlay__ {

				cpif {
					pinctrl-0 = <0x00>;
				};

				cp_shmem {
					memory-region = <0x04>;
				};
			};
		};

		fragment@model {

			__overlay__ {

				gpio_keys {
					pinctrl-0 = <0x00>;
				};

				gnssif {
					mbox_info = <0x00>;
				};
			};
		};
	};
};
